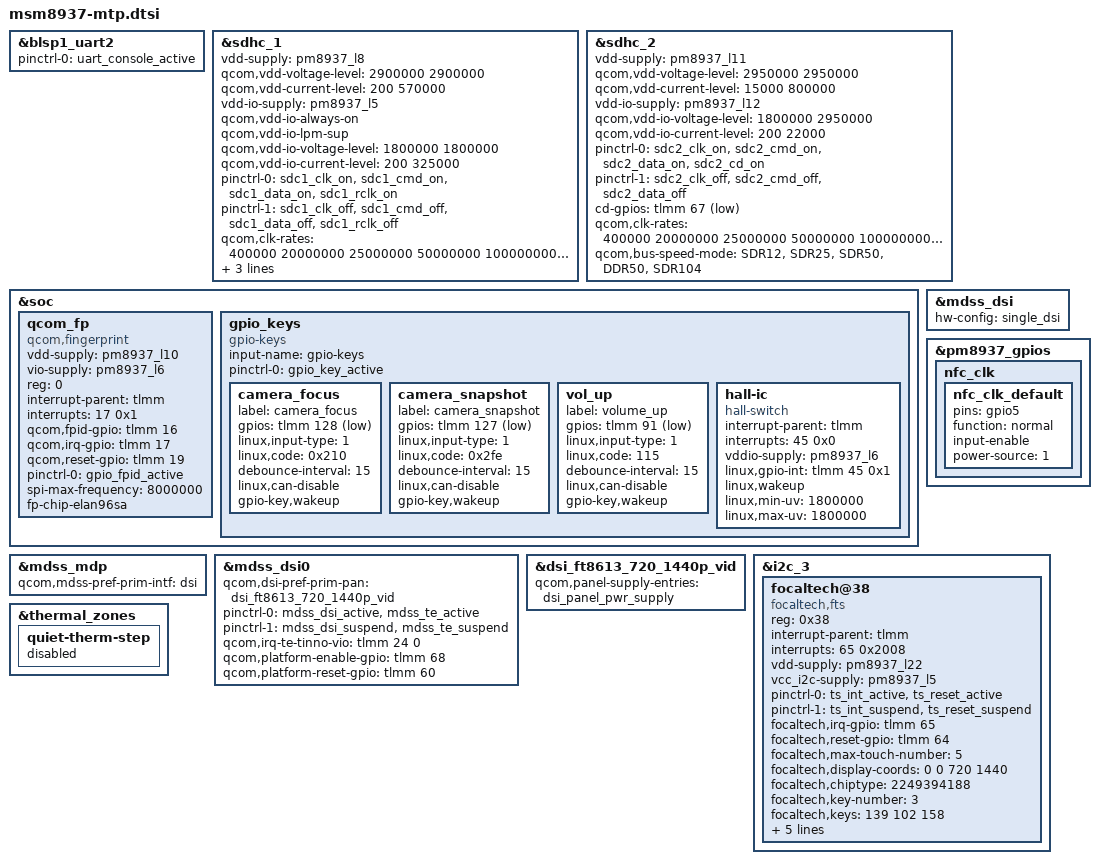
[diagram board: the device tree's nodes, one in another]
/*
 * Copyright (c) 2015-2016, 2018, The Linux Foundation. All rights reserved.
 *
 * This program is free software; you can redistribute it and/or modify
 * it under the terms of the GNU General Public License version 2 and
 * only version 2 as published by the Free Software Foundation.
 *
 * This program is distributed in the hope that it will be useful,
 * but WITHOUT ANY WARRANTY; without even the implied warranty of
 * MERCHANTABILITY or FITNESS FOR A PARTICULAR PURPOSE.  See the
 * GNU General Public License for more details.
 */

#include "msm8937-camera-sensor-mtp.dtsi"

#include "msm8937-pinctrl.dtsi"
&blsp1_uart2 {
	status = "ok";
	pinctrl-names = "default";
	pinctrl-0 = <&uart_console_active>;
};

&sdhc_1 {
	/* device core power supply */
	vdd-supply = <&pm8937_l8>;
	qcom,vdd-voltage-level = <2900000 2900000>;
	qcom,vdd-current-level = <200 570000>;

	/* device communication power supply */
	vdd-io-supply = <&pm8937_l5>;
	qcom,vdd-io-always-on;
	qcom,vdd-io-lpm-sup;
	qcom,vdd-io-voltage-level = <1800000 1800000>;
	qcom,vdd-io-current-level = <200 325000>;

	pinctrl-names = "active", "sleep";
	pinctrl-0 = <&sdc1_clk_on &sdc1_cmd_on &sdc1_data_on &sdc1_rclk_on>;
	pinctrl-1 = <&sdc1_clk_off &sdc1_cmd_off &sdc1_data_off &sdc1_rclk_off>;

	qcom,clk-rates = <400000 20000000 25000000 50000000 100000000 192000000
								384000000>;
	qcom,nonremovable;
	qcom,bus-speed-mode = "HS400_1p8v", "HS200_1p8v", "DDR_1p8v";

	status = "ok";
};

&sdhc_2 {
	/* device core power supply */
	vdd-supply = <&pm8937_l11>;
	qcom,vdd-voltage-level = <2950000 2950000>;
	qcom,vdd-current-level = <15000 800000>;

	/* device communication power supply */
	vdd-io-supply = <&pm8937_l12>;
	qcom,vdd-io-voltage-level = <1800000 2950000>;
	qcom,vdd-io-current-level = <200 22000>;

	pinctrl-names = "active", "sleep";
	pinctrl-0 = <&sdc2_clk_on &sdc2_cmd_on &sdc2_data_on &sdc2_cd_on>;
	pinctrl-1 = <&sdc2_clk_off &sdc2_cmd_off &sdc2_data_off>;

	cd-gpios = <&tlmm 67 0x1>;

	qcom,clk-rates = <400000 20000000 25000000 50000000 100000000
								200000000>;
	qcom,bus-speed-mode = "SDR12", "SDR25", "SDR50", "DDR50", "SDR104";

	status = "ok";
};

//TINNO BEGIN
//DATE20171103, Added For ELAN FP By qiao.li,IAAO-141
&soc {
	qcom_fp{
		status = "ok";
		compatible = "qcom,fingerprint";
		vdd-supply = <&pm8937_l10>;
		vio-supply = <&pm8937_l6>;
		reg = <0>;
		interrupt-parent = <&tlmm>;
		interrupts = <17 0x1>;
		qcom,fpid-gpio = <&tlmm 16 0x00>;
		qcom,irq-gpio = <&tlmm 17 0x00>;
		qcom,reset-gpio = <&tlmm 19 0x00>;
		pinctrl-names = "tlmm_gpio_fpid_active";
		pinctrl-0 = <&gpio_fpid_active>;
		spi-max-frequency = <8000000>;
		fp-chip-elan96sa;
	};
};
//TINNO END

#include "msm8937-mdss-panels.dtsi"

&mdss_mdp {
	qcom,mdss-pref-prim-intf = "dsi";
};

&mdss_dsi {
	hw-config = "single_dsi";
};

&mdss_dsi0 {
	qcom,dsi-pref-prim-pan = <&dsi_ft8613_720_1440p_vid>;
	pinctrl-names = "mdss_default", "mdss_sleep";
	pinctrl-0 = <&mdss_dsi_active &mdss_te_active>;
	pinctrl-1 = <&mdss_dsi_suspend &mdss_te_suspend>;

	qcom,irq-te-tinno-vio = <&tlmm 24 0>;
	//qcom,platform-te-gpio = <&tlmm 24 0>;
	qcom,platform-enable-gpio = <&tlmm 68 0>;
	qcom,platform-reset-gpio = <&tlmm 60 0>;
	//qcom,platform-bklight-en-gpio = <&tlmm 59 0>;
};

&dsi_ft8613_720_1440p_vid {
	qcom,panel-supply-entries = <&dsi_panel_pwr_supply>;
};

&soc {
	gpio_keys {
		compatible = "gpio-keys";
		input-name = "gpio-keys";
		pinctrl-names = "default";
		pinctrl-0 = <&gpio_key_active>;

		camera_focus {
			label = "camera_focus";
			gpios = <&tlmm 128 0x1>;
			linux,input-type = <1>;
			linux,code = <0x210>;
			debounce-interval = <15>;
			linux,can-disable;
			gpio-key,wakeup;
		};

		camera_snapshot {
			label = "camera_snapshot";
			gpios = <&tlmm 127 0x1>;
			linux,input-type = <1>;
			linux,code = <0x2fe>;
			debounce-interval = <15>;
			linux,can-disable;
			gpio-key,wakeup;
		};

		vol_up {
			label = "volume_up";
			gpios = <&tlmm 91 0x1>;
			linux,input-type = <1>;
			linux,code = <115>;
			debounce-interval = <15>;
			linux,can-disable;
			gpio-key,wakeup;
		};

		//wangyanhui add hall ic
		hall-ic {
			compatible = "hall-switch";
			//pinctrl-names = "default";
			//pinctrl-0 = <&hall_sensor_int_default>;
			interrupt-parent = <&tlmm>;
			interrupts = <45 0x0>;
			vddio-supply = <&pm8937_l6>;
			linux,gpio-int = <&tlmm 45 0x1>;
			linux,wakeup;
			linux,min-uv = <1800000>;
			linux,max-uv = <1800000>;
		};

	};
};

&pm8937_gpios {
	nfc_clk {
		nfc_clk_default: nfc_clk_default {
			pins = "gpio5";
			function = "normal";
			input-enable;
			power-source = <1>;
		};
	};
};

&i2c_3{
	focaltech@38 {
		compatible = "focaltech,fts";
		reg = <0x38>;
		interrupt-parent = <&tlmm>;
		interrupts = <65 0x2008>;
		vdd-supply = <&pm8937_l22>;
		vcc_i2c-supply = <&pm8937_l5>;
		/* pins used by touchscreen */
		pinctrl-names = "pmx_ts_active","pmx_ts_suspend";//,"pmx_ts_release";
		pinctrl-0 = <&ts_int_active &ts_reset_active>;
		pinctrl-1 = <&ts_int_suspend &ts_reset_suspend>;
		//pinctrl-2 = <&ts_release>;
		focaltech,irq-gpio = <&tlmm 65 0x0>;
		focaltech,reset-gpio = <&tlmm 64 0x0>;
		focaltech,max-touch-number = <5>;
		focaltech,display-coords = <0 0 720 1440>;
		focaltech,chiptype = <2249394188>;
		//focaltech,have-key;
		focaltech,key-number = <3>;
		focaltech,keys = <139 102 158>;
		focaltech,key-y-coord = <2000>;
		focaltech,key-x-coords = <200 600 800>;
		//focaltech,multi-vendor-with-same-ic;
		//focaltech,tp_forceupgrade-deviceid = <0x54>;
		focaltech,fw-auto-update;
		focaltech,display-cfg-auto-update;
		focaltech,multiple-ic;
	};
};

&thermal_zones {
	quiet-therm-step {
		status = "disabled";
	};
};
